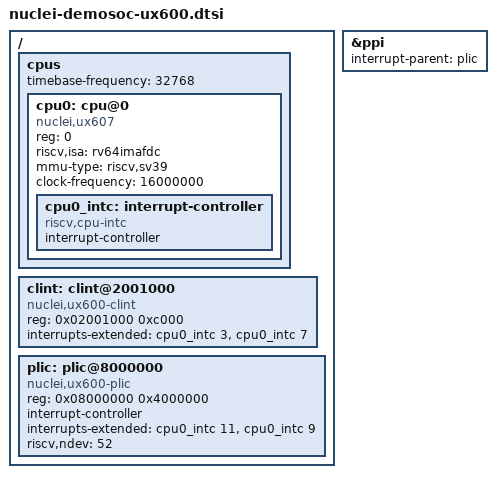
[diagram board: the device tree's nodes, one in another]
// SPDX-License-Identifier: (GPL-2.0 OR MIT)
/* Copyright (c) 2022 Nuclei System Technology */

#include "nuclei-demosoc.dtsi"

/ {
	cpus {
		#address-cells = <1>;
		#size-cells = <0>;
		/* The counting clock of the timer is the LF clock */
		timebase-frequency = <32768>;

		cpu0: cpu@0 {
			compatible = "nuclei,ux607", "nuclei,ux600", "riscv";
			device_type = "cpu";
			reg = <0>;
			riscv,isa = "rv64imafdc";
			mmu-type = "riscv,sv39";
			clock-frequency = <16000000>;

			cpu0_intc: interrupt-controller {
				#interrupt-cells = <1>;
				compatible = "riscv,cpu-intc";
				interrupt-controller;
			};
		};
	};

	clint: clint@2001000 {
		compatible = "nuclei,ux600-clint", "sifive,clint0";
		reg = <0x02001000 0xc000>;
		interrupts-extended = <&cpu0_intc 3>, <&cpu0_intc 7>;
	};

	plic: plic@8000000 {
		compatible = "nuclei,ux600-plic", "sifive,plic-1.0.0";
		reg = <0x08000000 0x4000000>;
		#address-cells = <0>;
		#interrupt-cells = <1>;
		interrupt-controller;
		interrupts-extended =
			<&cpu0_intc 11>, <&cpu0_intc 9>;
		riscv,ndev = <52>;
	};
};

&ppi {
	interrupt-parent = <&plic>;
};
